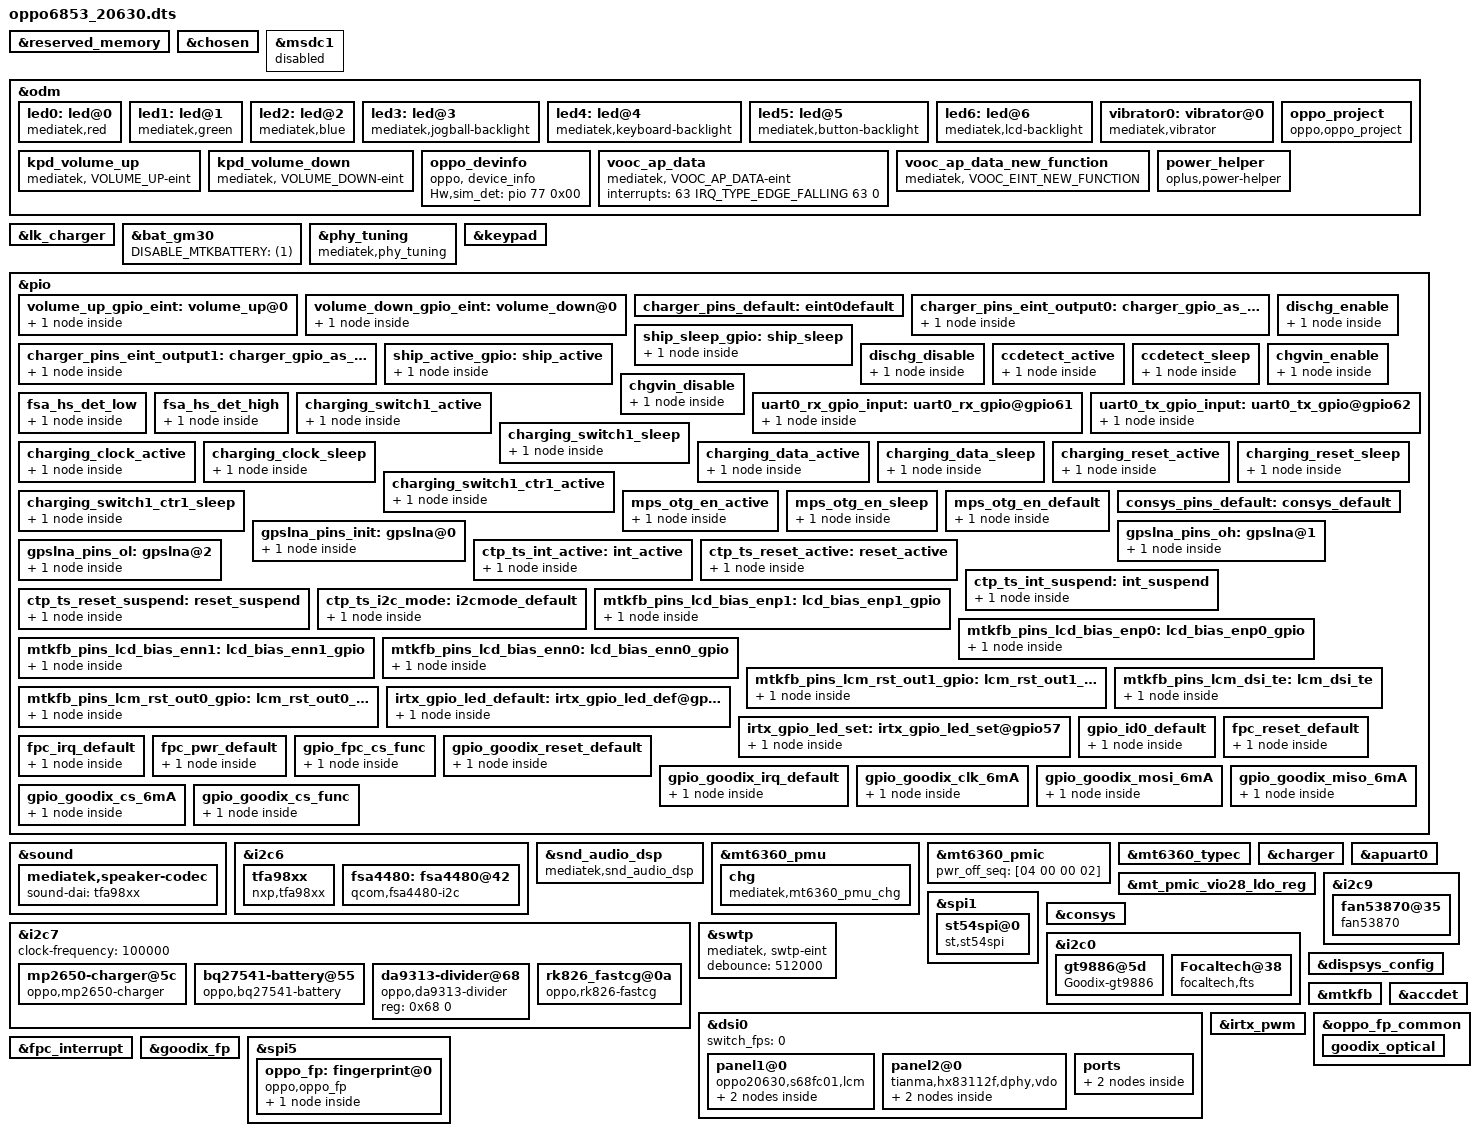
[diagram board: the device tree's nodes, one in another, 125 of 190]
/*
 * Mediatek's mt6853 SoC device tree source
 *
 * Copyright (C) 2016 MediaTek Inc.
 *
 * This program is free software; you can redistribute it and/or modify
 * it under the terms of the GNU General Public License version 2 as
 * published by the Free Software Foundation.
 *
 * This program is distributed in the hope that it will be useful,
 * but WITHOUT ANY WARRANTY; without even the implied warranty of
 * MERCHANTABILITY or FITNESS FOR A PARTICULAR PURPOSE.
 * See http://www.gnu.org/licenses/gpl-2.0.html for more details.
 */
/dts-v1/;
/plugin/;
#include <dt-bindings/interrupt-controller/irq.h>
#include <dt-bindings/interrupt-controller/arm-gic.h>
#include <dt-bindings/pinctrl/mt6853-pinfunc.h>

&reserved_memory {
};

/* chosen */
&chosen {

	atag,videolfb-fb_base_l = <0x7e605000>;
	atag,videolfb-fb_base_h = <0x0>;
	atag,videolfb-islcmfound = <1>;
	atag,videolfb-islcm_inited = <0>;
	atag,videolfb-fps= <6000>;
	atag,videolfb-vramSize= <0x1be0000>;
	atag,videolfb-lcmname=
		"nt35595_fhd_dsi_cmd_truly_nt50358_drv";
};

//ifdef VENDOR_EDIT
/*WeiZhenXi@RM.BSP.Storage.sdcard disable msdc1 for screen*/
&msdc1 {
	status = "disable";
};
//endif VENDOR_EDIT
&odm {
	led0:led@0 {
		compatible = "mediatek,red";
		led_mode = <0>;
		data = <1>;
		pwm_config = <0 0 0 0 0>;
	};
	led1:led@1 {
		compatible = "mediatek,green";
		led_mode = <0>;
		data = <1>;
		pwm_config = <0 0 0 0 0>;
	};
	led2:led@2 {
		compatible = "mediatek,blue";
		led_mode = <0>;
		data = <1>;
		pwm_config = <0 0 0 0 0>;
	};
	led3:led@3 {
		compatible = "mediatek,jogball-backlight";
		led_mode = <0>;
		data = <1>;
		pwm_config = <0 0 0 0 0>;
	};
	led4:led@4 {
		compatible = "mediatek,keyboard-backlight";
		led_mode = <0>;
		data = <1>;
		pwm_config = <0 0 0 0 0>;
	};
	led5:led@5 {
		compatible = "mediatek,button-backlight";
		led_mode = <0>;
		data = <1>;
		pwm_config = <0 0 0 0 0>;
	};
	led6:led@6 {
		compatible = "mediatek,lcd-backlight";
		led_mode = <4>;
		data = <1>;
		pwm_config = <0 1 0 0 0>;
	};
	vibrator0:vibrator@0 {
		compatible = "mediatek,vibrator";
		//#ifdef VENDOR_EDIT
		/* Xing.Xiong@EXP.BSP.Kernel.Driver.998782, 2017/05/16, Modify for vibrator time less than 9ms */
		vib_timer = <30>;
		vib_limit = <0>;
		//#else
		//vib_timer = <25>;
		//vib_limit = <9>;
		//#endif /* VENDOR_EDIT */
		vib_vol= <11>;
	};
//	usb_c_pinctrl:usb_c_pinctrl {
//		compatible = "mediatek,usb_c_pinctrl";
//	};

/*VENDOR_EDIT keypad start*/
/*Bin.Li@EXP.BSP.bootloader.bootflow, 2017/05/16, Add volume up and down */
	kpd_volume_up:kpd_volume_up {
		compatible = "mediatek, VOLUME_UP-eint";
		interrupt-parent = <&pio>;
		interrupts = <1 IRQ_TYPE_EDGE_FALLING 1 0>;
		debounce = <32000>;
		status = "okay";
	};

	kpd_volume_down:kpd_volume_down {
		compatible = "mediatek, VOLUME_DOWN-eint";
		interrupt-parent = <&pio>;
		interrupts = <80 IRQ_TYPE_EDGE_FALLING 80 0>;
		debounce = <32000>;
		status = "okay";
	};
/*VENDOR_EDIT keypad end*/

//#ifdef VENDOR_EDIT
/*Bin.Li@EXP.BSP.bootloader.bootflow, 2017/05/15, Add for oppo project */
	oppo_project:oppo_project {
		compatible = "oppo,oppo_project";
	};
	oppo_devinfo:oppo_devinfo {
		compatible = "oppo, device_info";
	};
//#endif /*VENDOR_EDIT*/
	vooc_ap_data:vooc_ap_data {
		compatible = "mediatek, VOOC_AP_DATA-eint";
		interrupts = <63 IRQ_TYPE_EDGE_FALLING 63 0>;
	};
	vooc_ap_data_new_function:vooc_ap_data_new_function {
		compatible = "mediatek, VOOC_EINT_NEW_FUNCTION";
	};

};

&lk_charger{
	charger_by_buckboost;
	chgic_id = <0>;
};
&bat_gm30 {
	DISABLE_MTKBATTERY = <(1)>;
};
&phy_tuning {
	compatible = "mediatek,phy_tuning";
	u2_vrt_ref = <7>;
	u2_term_ref = <7>;
	u2_enhance = <3>;

	host_u2_vrt_ref = <6>;
	host_u2_term_ref = <6>;
	host_u2_enhance = <2>;
};
/*VENDOR_EDIT*/
/*Bin.Li@EXP.BSP.bootloader.bootflow, 2017/05/16, Add volume up and down*/
&keypad {
	keypad,volume-up	= <&pio 1 0x00>;
	keypad,volume-down	= <&pio 80 0x00>;
	pinctrl-names = "volume_up_as_int", "volume_down_as_int";
	pinctrl-0 = <&volume_up_gpio_eint>;
	pinctrl-1 = <&volume_down_gpio_eint>;
	status = "okay";
};
&pio {
	volume_up_gpio_eint:volume_up@0{
		pins_cmd_dat {
			pinmux = <PINMUX_GPIO1__FUNC_GPIO1>;
			slew-rate = <0>;  /*direction 0:in, 1:out*/
			input-enable;
		};
	};

	volume_down_gpio_eint:volume_down@0{
		pins_cmd_dat {
			pinmux = <PINMUX_GPIO80__FUNC_GPIO80>;
			slew-rate = <0>;  /*direction 0:in, 1:out*/
			input-enable;
		};
	};
};
/*VENDOR_EDIT*/

&oppo_devinfo {
	Hw,sim_det = <&pio 77 0x00>;
};

/*VENDOR_EDIT*/
/* Hefeng.Wu@RM.MM.AudioDriver.Platform, 2020/06/05, add for project compatible */
&sound {
	mediatek,speaker-codec {
		sound-dai = <&tfa98xx>;
	};
};

&i2c6 {
    #address-cells = <1>;
    #size-cells = <0>;

    tfa98xx: tfa98xx {
        compatible = "nxp,tfa98xx";
        reg = <0x34>;
        #sound-dai-cells = <0>;
        reset-gpio = <&pio 139 0>;
        tfa_min_range = <5000>;
        tfa_max_range = <8000>;
        status = "okay";
    };

    fsa4480: fsa4480@42 {
        compatible = "qcom,fsa4480-i2c";
        reg = <0x42>;
        pinctrl-names = "hs_det_gpio_low","hs_det_gpio_high";
        pinctrl-0 = <&fsa_hs_det_low>;
        pinctrl-1 = <&fsa_hs_det_high>;
        fsa4480,hs-det-gpio = <&pio 128 0>;
    };
};
/*VENDOR_EDIT*/

&snd_audio_dsp {
	compatible = "mediatek,snd_audio_dsp";
	mtk_dsp_voip = <0x1f 0x1 0xffffffff 0xffffffff 0x30000>;
	mtk_dsp_primary = <0x1f 0x0 0xffffffff 0xffffffff 0x30000>;
	mtk_dsp_offload = <0x0 0x6 0xffffffff 0xffffffff 0x400000>;
	mtk_dsp_deep = <0x5 0x3 0xffffffff 0xffffffff 0x30000>;
	mtk_dsp_playback = <0x1 0x4 0x10 0x14 0x30000>;
	mtk_dsp_music = <0x1 0xffffffff 0xffffffff 0xffffffff 0x0>;
	mtk_dsp_capture1 = <0x1 0xffffffff 0xd 0x13 0x20000>;
	mtk_dsp_a2dp = <0x0 0xffffffff 0xffffffff 0xffffffff 0x40000>;
	mtk_dsp_dataprovider = <0x0 0xffffffff 0xf 0xffffffff 0x30000>;
	mtk_dsp_call_final = <0x1 0x4 0x10 0x14 0x18000>;
	mtk_dsp_fast = <0x5 0x2 0xffffffff 0xffffffff 0x5000>;
	mtk_dsp_ktv = <0x1 0x8 0x12 0xffffffff 0x10000>;
	mtk_dsp_ver = <0x1>;
	swdsp_smartpa_process_enable = <0x1 0x40000>;
};


/* Charging Start */

&mt6360_pmu {
	mt6360,intr_gpio_num = <10>; /* direct defined GPIO num */
	mt6360,intr_gpio = <&pio 10 0x0>;
};

&mt6360_pmic {
	pwr_off_seq = [04 00 00 02];
};

&mt6360_typec {
	mt6360pd,intr_gpio_num = <9>; /* direct defined GPIO num */
	mt6360pd,intr_gpio = <&pio 9 0x0>;
	//mt6360pd,pcb_gpio = <&pio 57 0x0>;
	//mt6360pd,pcb_gpio_num = <57>;
	mt-tcpc,role_def = <4>;
};

&mt6360_pmu {
	chg {
		compatible = "mediatek,mt6360_pmu_chg";
		interrupt-parent = <&mt6360_pmu>;
		interrupts = <4 0>, <6 0>, <7 0>, <9 0>,
				<12 0>, <13 0>, <14 0>, <15 0>,
				<27 0>, <29 0>, <30 0>, <32 0>,
				<35 0>, <40 0>, <48 0>, <60 0>,
				<53 0>;
		interrupt-names = "chg_treg_evt", "chg_mivr_evt",
				"pwr_rdy_evt", "chg_batsysuv_evt",
				"chg_vsysuv_evt", "chg_vsysov_evt",
				"chg_vbatov_evt", "chg_vbusov_evt",
				"chg_tmri", "chg_adpbadi",
				"chg_rvpi",  "chg_aiccmeasl",
				"wdtmri", "pumpx_donei",
				"attachi", "chrdet_ext_evt",
				"hvdcp_det";
		io-channels = <&adc 0>, <&adc 1>, <&adc 3>, <&adc 4>,
				<&adc 5>, <&adc 6>, <&adc 8>, <&adc 10>;
		io-channel-names = "USBID", "VBUSDIV5", "VSYS", "VBAT",
				"IBUS", "IBAT", "TEMP_JC", "TS";
		chg_name = "primary_chg";
		ichg = <2000000>;               /* uA */
		aicr = <500000>;                /* uA */
		mivr = <4400000>;               /* uV */
		cv = <4350000>;                 /* uA */
		ieoc = <150000>;                /* uA */
		safety_timer = <12>;            /* hour */
		ircmp_resistor = <25000>;       /* uohm */
		ircmp_vclamp = <32000>;         /* uV */
		en_te = <1>;
		en_wdt = <1>;
		aicc_once = <1>;
		post_aicc = <1>;
		batoc_notify = <0>;
	};
};



&charger {
	io-channels = <&auxadc 3>,
		<&auxadc 4>,
		<&auxadc 5>;
	io-channel-names = "auxadc3-charger_id",
		"auxadc4-usb_temp_v_l",
		"auxadc5-usb_temp_v_r";

	pinctrl-names = "default", "charger_gpio_as_output_low", "charger_gpio_as_output_high", "ship_sleep", "ship_active", 
		"dischg_enable", "dischg_disable",
		"chgvin_enable", "chgvin_disable",
		"ccdetect_active","ccdetect_sleep";
	pinctrl-0 = <&charger_pins_default>;
	pinctrl-1 = <&charger_pins_eint_output0>;//USB_ON
	pinctrl-2 = <&charger_pins_eint_output1>;//USB_ON
	pinctrl-3 = <&ship_sleep_gpio>;
	pinctrl-4 = <&ship_active_gpio>;
	pinctrl-5 = <&dischg_enable>;
	pinctrl-6 = <&dischg_disable>;
	pinctrl-7 = <&chgvin_enable>;
	pinctrl-8 = <&chgvin_disable>;
	//pinctrl-5 = <&shortc_active_gpio>;
	pinctrl-9 = <&ccdetect_active>;
	pinctrl-10 = <&ccdetect_sleep>;

	qcom,input_current_charger_ma = <2000>;
	qcom,pd_input_current_charger_ma = <2000>;
	qcom,qc_input_current_charger_ma = <2000>;
	qcom,input_current_usb_ma = <500>;

	qcom,input_current_cdp_ma = <1500>;
	qcom,input_current_led_ma = <1200>;
	qcom,input_current_led_ma_high = <1200>;
	qcom,input_current_led_ma_warm = <1500>;
	qcom,input_current_led_ma_normal = <2000>;
	qcom,led_warm_bat_decidegc = <350>;
	qcom,led_high_bat_decidegc = <370>;

	qcom,input_current_camera_ma = <1200>;
			
	qcom,input_current_vooc_led_ma_high = <1200>;
	qcom,input_current_vooc_led_ma_warm = <1800>;
	qcom,input_current_vooc_led_ma_normal = <3600>;
	qcom,input_current_vooc_ma_normal = <3600>;
	qcom,vooc_temp_bat_normal_decidegc = <350>;
	qcom,input_current_vooc_ma_warm = <3200>;
	qcom,vooc_temp_bat_warm_decidegc = <370>;
	qcom,input_current_vooc_ma_high = <2200>;
	qcom,vooc_temp_bat_hot_decidegc = <440>;

	qcom,charger_current_vooc_ma_normal = <1800>;

	qcom,chg_ctrl_by_calling;
	qcom,input_current_calling_ma = <1500>;

	qcom,overtemp_bat_decidegc = <350>;
	qcom,iterm_disabled = <0>;
	qcom,iterm_ma = <115>;
	qcom,recharge-mv = <100>;
	qcom,batt_capacity_mah = <4300>;/*typical capacity*/

	qcom,removed_bat_decidegc = <190>;  /*<-19C*/

	qcom,cold_bat_decidegc = <20>;  /*-2C~0C*/
	qcom,temp_cold_vfloat_mv = <3980>;
	qcom,temp_cold_fastchg_current_ma = <300>;

	qcom,little_cold_bat_decidegc = <0>;    /*0C~5C*/
	qcom,temp_little_cold_vfloat_mv = <4435>;
	qcom,temp_little_cold_fastchg_current_ma_high = <950>;
	qcom,temp_little_cold_fastchg_current_ma_low = <950>;
	qcom,temp_little_cold_fastchg_current_ma = <950>;
	qcom,pd_temp_little_cold_fastchg_current_ma_high = <1800>;
	qcom,pd_temp_little_cold_fastchg_current_ma_low = <1500>;
	qcom,qc_temp_little_cold_fastchg_current_ma_high = <1800>;
	qcom,qc_temp_little_cold_fastchg_current_ma_low = <1500>;

	qcom,cool_bat_decidegc = <50>;  /*5C~12C*/
	qcom,temp_cool_vfloat_mv = <4435>;
	qcom,temp_cool_fastchg_current_ma_high = <1100>;
	qcom,temp_cool_fastchg_current_ma_low = <1100>;
	qcom,pd_temp_cool_fastchg_current_ma_high = <2000>;
	qcom,pd_temp_cool_fastchg_current_ma_low = <1500>;
	qcom,qc_temp_cool_fastchg_current_ma_high = <2000>;
	qcom,qc_temp_cool_fastchg_current_ma_low = <1500>;

	qcom,little_cool_bat_decidegc = <120>;  /*12C~16C*/
	qcom,temp_little_cool_vfloat_mv = <4435>;
	qcom,temp_little_cool_fastchg_current_ma = <1100>;
	qcom,pd_temp_little_cool_fastchg_current_ma = <2000>;
	qcom,qc_temp_little_cool_fastchg_current_ma = <2000>;

	qcom,normal_bat_decidegc = <160>;       /*16C~44C*/
	qcom,temp_normal_fastchg_current_ma = <1100>;
	qcom,temp_normal_vfloat_mv = <4435>;
	qcom,pd_temp_normal_fastchg_current_ma = <2000>;
	qcom,qc_temp_normal_fastchg_current_ma = <2000>;

	qcom,warm_bat_decidegc = <450>;         /*45C~53C*/ /*8pin Bat Vooc project need add 3 degree C*/
	qcom,temp_warm_vfloat_mv = <4130>;
	qcom,temp_warm_fastchg_current_ma = <550>;
	qcom,pd_temp_warm_fastchg_current_ma = <600>;
	qcom,qc_temp_warm_fastchg_current_ma = <600>;
	qcom,temp_warm_fastchg_current_ma_led_on = <250>;

	qcom,hot_bat_decidegc = <530>;

	qcom,non_standard_vfloat_mv = <3980>;
	qcom,non_standard_fastchg_current_ma = <512>;

	qcom,short_c_bat_cv_mv = <4330>;
	qcom,short_c_bat_vfloat_mv = <3800>;
	qcom,short_c_bat_fastchg_current_ma = <512>;

	qcom,cold_vfloat_sw_limit = <3930>;
	qcom,little_cold_vfloat_sw_limit = <4385>;
	qcom,cool_vfloat_sw_limit = <4385>;
	qcom,little_cool_vfloat_sw_limit = <4385>;
	qcom,normal_vfloat_sw_limit = <4385>;
	qcom,warm_vfloat_sw_limit = <4080>;
	qcom,non_standard_vfloat_sw_limit = <3930>;
	qcom,short_c_bat_vfloat_sw_limit = <3750>;

	qcom,max_chg_time_sec = <61920>;
	qcom,charger_hv_thr = <9900>;
	qcom,charger_recv_thr = <9500>;
	qcom,charger_lv_thr = <3400>;
	qcom,vbatt_full_thr = <4435>;
	qcom,vbatt_hv_thr = <4600>;
	qcom,vfloat_step_mv = <8>;
	qcom,non_standard_vfloat_over_sw_limit = <3990>;
	qcom,cold_vfloat_over_sw_limit = <3990>;
	qcom,little_cold_vfloat_over_sw_limit = <4445>;
	qcom,cool_vfloat_over_sw_limit = <4445>;
	qcom,little_cool_vfloat_over_sw_limit = <4445>;
	qcom,normal_vfloat_over_sw_limit = <4445>;
	qcom,warm_vfloat_over_sw_limit = <4140>;

	qcom,vbatt_power_off = <3300>;
	qcom,vbatt_soc_1 = <3310>;
	qcom,vooc_project = <3>;
	qcom,vbatt_num = <2>;
	qcom,new_ui_warning_support;
	qcom,ffc_support;
	qcom,dual_ffc;
	recharge_after_full;

	qcom,normal_vterm_hw_inc = <18>;
	qcom,non_normal_vterm_hw_inc = <18>;

	qcom,ff1_normal_fastchg_ma = <550>;
	qcom,ff1_warm_fastchg_ma = <550>;

	qcom,ffc2_normal_fastchg_ma = <350>;/*12C~35c*/
	qcom,ffc2_temp_warm_decidegc = <350>;
	qcom,ffc2_warm_fastchg_ma = <350>;/*35C~40c*/
	qcom,ffc2_temp_high_decidegc = <400>;
	qcom,ffc2_temp_low_decidegc = <120>;
	qcom,ffc2_exit_step_ma = <150>;
	qcom,ff1_exit_step_ma = <150>;
	qcom,ff1_warm_exit_step_ma = <150>;

	qcom,ffc_normal_vfloat_sw_limit = <4455>;
	qcom,ffc_warm_vfloat_sw_limit = <4450>;
	qcom,ffc2_normal_vfloat_sw_limit = <4445>;
	qcom,ffc2_warm_vfloat_sw_limit = <4440>;
	qcom,ffc_temp_normal_vfloat_mv = <4500>;
	qcom,ffc1_temp_normal_vfloat_mv = <4500>;
	qcom,ffc2_temp_normal_vfloat_mv = <4500>;
	qcom,ffc_normal_vfloat_over_sw_limit = <4500>;
	qcom,ffc1_normal_vfloat_over_sw_limit = <4500>;
	qcom,ffc2_normal_vfloat_over_sw_limit = <4500>;

	qcom,default_iterm_ma = <115>;
	qcom,default_temp_normal_fastchg_current_ma = <1100>;
	qcom,default_normal_vfloat_sw_limit = <4385>;
	qcom,default_temp_normal_vfloat_mv = <4435>;
	qcom,default_normal_vfloat_over_sw_limit = <4445>;

	qcom,default_temp_little_cool_fastchg_current_ma = <1100>;
	qcom,default_little_cool_vfloat_sw_limit = <4385>;
	qcom,default_temp_little_cool_vfloat_mv = <4435>;
	qcom,default_little_cool_vfloat_over_sw_limit = <4445>;

	qcom,check_batt_full_by_sw;
	qcom,external_gauge;
	qcom,chg_ctrl_by_lcd;
	qcom,chg_ctrl_by_vooc;
	qcom,chg_ctrl_by_camera;
	qcom,sw_vfloat_over_protect_enable;
	qcom,lpd-disable;
	qcom,hv_flashled_support;
	//for PD9V or QC9V
	qcom,vbatt_pdqc_to_5v_thr = <4100>;

	//GPIO config:
	qcom,chargerid_switch-gpio = <&pio 40 0x00>;//USB_ON
	qcom,ship-gpio = <&pio 16 0x00>;
	qcom,dischg-gpio = <&pio 39 0x00>;//VBUS_SHORT
	//qcom,shortc-gpio = <&pio 121 0x00>;
	qcom,chgvin = <&pio 131 0x00>;
	qcom,ccdetect-gpio = <&pio 92 0x00>;//USB_ACC_INT
};
//#ifdef VENDOR_EDIT
//laq@PSW.BSP.sensor, 2020/04/26, Add for 20001 als&ps
&mt_pmic_vio28_ldo_reg {
	regulator-name = "vio28";
	regulator-min-microvolt = <3000000>;
	regulator-max-microvolt = <3000000>;
	regulator-enable-ramp-delay = <240>;
};
//#endif /* VENDOR_EDIT */

&pio {
	charger_pins_default: eint0default {
	};

	charger_pins_eint_output0: charger_gpio_as_output_low {
		pins_cmd_dat {
			pinmux = <PINMUX_GPIO40__FUNC_GPIO40>;
			slew-rate = <1>;
			output-low;
		};
	};

	charger_pins_eint_output1: charger_gpio_as_output_high {
		pins_cmd_dat {
			pinmux = <PINMUX_GPIO40__FUNC_GPIO40>;
			slew-rate = <1>;
			output-high;
		};
	};

	ship_sleep_gpio: ship_sleep {
		pins_cmd_dat {
			pinmux = <PINMUX_GPIO16__FUNC_GPIO16>;
			slew-rate = <1>;
			output-low;
		};
	};

	ship_active_gpio: ship_active {
		pins_cmd_dat {
			pinmux = <PINMUX_GPIO16__FUNC_GPIO16>;
			slew-rate = <1>;
			output-high;
		};
	};
	dischg_enable: dischg_enable {
		pins_cmd_dat {
			pinmux = <PINMUX_GPIO39__FUNC_GPIO39>;
			slew-rate = <1>;//0:input direction 1:output direction
			bias-pull-up = <00>;
			output-high;
		};
	};

	dischg_disable: dischg_disable {
		pins_cmd_dat {
			pinmux = <PINMUX_GPIO39__FUNC_GPIO39>;
			slew-rate = <1>;
			bias-pull-down = <00>;
			output-low;
		};
	};

	
	ccdetect_active: ccdetect_active {
		pins_cmd_dat {
			pinmux = <PINMUX_GPIO92__FUNC_GPIO92>;
			input-enable;
			slew-rate = <0>;
			bias-disable;
		};
	};

	ccdetect_sleep: ccdetect_sleep {
		pins_cmd_dat {
			pinmux = <PINMUX_GPIO92__FUNC_GPIO92>;
			input-enable;
			slew-rate = <0>;
			bias-disable;
		};
	};
	chgvin_enable: chgvin_enable {
		pins_cmd_dat {
			pinmux = <PINMUX_GPIO131__FUNC_GPIO131>;
			slew-rate = <1>;//0:input direction 1:output direction
			bias-pull-up = <00>;
			output-low;
		};
	};
	chgvin_disable: chgvin_disable {
		pins_cmd_dat {
			pinmux = <PINMUX_GPIO131__FUNC_GPIO131>;
			slew-rate = <1>;
			bias-pull-down = <00>;
			output-high;
		};
	};
    fsa_hs_det_low: fsa_hs_det_low {
        pins_cmd_dat {
            pinmux = <PINMUX_GPIO128__FUNC_GPIO128>;
            slew-rate = <1>;  /*direction 0:in, 1:out*/
            output-low;
        };
    };

    fsa_hs_det_high: fsa_hs_det_high {
        pins_cmd_dat {
            pinmux = <PINMUX_GPIO128__FUNC_GPIO128>;
            slew-rate = <1>;  /*direction 0:in, 1:out*/
            output-high;
        };
    };
};

//#ifdef VENDOR_EDIT
//LiYue@BSP.CHG.Basic, 2019/10/02, Add for chargerid
&apuart0 {
	pinctrl-names = "uart0_rx_gpio",
			"uart0_tx_gpio";
	pinctrl-0 = <&uart0_rx_gpio_input>;
	pinctrl-1 = <&uart0_tx_gpio_input>;
	status = "okay";
};

&pio {
	uart0_rx_gpio_input:uart0_rx_gpio@gpio61 {
		pins_cmd_dat {
			pinmux = <PINMUX_GPIO61__FUNC_GPIO61>;
			input-enable;
			slew-rate = <0>;
			bias-disable;
		};
	};
	uart0_tx_gpio_input:uart0_tx_gpio@gpio62 {
		pins_cmd_dat {
			pinmux = <PINMUX_GPIO62__FUNC_GPIO62>;
			input-enable;
			slew-rate = <0>;
			bias-disable;
		};
	};
};

//#endif /* VENDOR_EDIT */





&i2c7 {
	status = "okay";
	clock-frequency = <100000>;
	mp2650-charger@5c {
		status = "okay";
		compatible = "oppo,mp2650-charger";
		reg = <0x5c>;
		qcom,mps_otg_en-gpio = <&pio 17 0x00>;
		pinctrl-names = "mps_otg_en_active", "mps_otg_en_sleep", "mps_otg_en_default";
		pinctrl-0 = <&mps_otg_en_active>;
		pinctrl-1 = <&mps_otg_en_sleep>;
		pinctrl-2 = <&mps_otg_en_default>;
	};
	bq27541-battery@55 {
		status = "okay";
		compatible = "oppo,bq27541-battery";
		reg = <0x55 0>;
		qcom,modify-soc-smooth;
		qcom,batt_bq28z610;
		//qcom,bq28z610_need_balancing;
	};

	da9313-divider@68 {
		status = "okay";
		compatible = "oppo,da9313-divider";
		reg = <0x68 0>;
		//qcom,ic_en_mode;
	};

	rk826_fastcg@0a{
		status = "okay";
		compatible = "oppo,rk826-fastcg";
		reg = <0x0a 0>;
		qcom,vooc-low-temp = <50>;
		qcom,oppo_batt_4400mv;
		qcom,support_vooc_by_normal_charger_path;
		qcom,vooc_fw_update_newmethod;
		qcom,vooc-high-temp = <430>;
		qcom,vooc-low-soc = <1>;
		qcom,vooc-high-soc = <90>;
		qcom,vooc-fw-type = <0x20>;

		qcom,vooc_multistep_adjust_current_support;
		qcom,vooc_multistep_initial_batt_temp = <310>;
		qcom,vooc_strategy_normal_current = <0x06>;

		qcom,vooc-normal-to-little-cool-current = <0x05>;
		qcom,vooc_batt_over_high_temp = <440>;
		qcom,vooc_batt_over_low_temp = <45>;
		qcom,vooc_over_high_or_low_current = <0x02>;

		qcom,vooc_strategy1_batt_high_temp0 = <425>;
		qcom,vooc_strategy1_batt_high_temp1 = <430>;
		qcom,vooc_strategy1_batt_high_temp2 = <435>;
		qcom,vooc_strategy1_batt_low_temp2 = <420>;
		qcom,vooc_strategy1_batt_low_temp1 = <415>;
		qcom,vooc_strategy1_batt_low_temp0 = <400>;

		qcom,vooc_strategy1_high_current0 = <0x04>;//4A
		qcom,vooc_strategy1_high_current1 = <0x03>;//3A
		qcom,vooc_strategy1_high_current2 = <0x02>;//2A
		qcom,vooc_strategy1_low_current2 = <0x03>;//3A
		qcom,vooc_strategy1_low_current1 = <0x04>;//4A
		qcom,vooc_strategy1_low_current0 = <0x04>;//4A

		qcom,vooc_strategy2_batt_up_temp1 = <375>;
		qcom,vooc_strategy2_batt_up_down_temp2 = <380>;
		qcom,vooc_strategy2_batt_up_temp3 = <390>;
		qcom,vooc_strategy2_batt_up_down_temp4 = <400>;
		qcom,vooc_strategy2_batt_up_temp5 = <410>;
		qcom,vooc_strategy2_batt_up_temp6 = <415>;
		qcom,vooc_strategy2_high0_current = <0x05>;
		qcom,vooc_strategy2_high1_current = <0x04>;
		qcom,vooc_strategy2_high2_current = <0x03>;
		qcom,vooc_strategy2_high3_current = <0x02>;
		pinctrl-names = "switch1_act_switch2_act", "switch1_sleep_switch2_sleep",
						"switch1_act_switch3_act", "switch1_sleep_switch3_sleep",
						"switch1_act_switch2_sleep", "switch1_sleep_switch2_act",
						"clock_active","clock_sleep",
						"data_active","data_sleep",
						"reset_active","reset_sleep",
						"charging_switch1_ctr1_active","charging_switch1_ctr1_sleep";
		pinctrl-0 = <&charging_switch1_active>;//USB_SW_CTRL1
		pinctrl-1 = <&charging_switch1_sleep>;//USB_SW_CTRL1
		pinctrl-2 = <&charging_switch1_active>;//USB_SW_CTRL1
		pinctrl-3 = <&charging_switch1_sleep>;//USB_SW_CTRL1
		pinctrl-4 = <&charging_switch1_active>;//USB_SW_CTRL1
		pinctrl-5 = <&charging_switch1_sleep>;//USB_SW_CTRL1
		pinctrl-6 = <&charging_clock_active>;//AP_CLK
		pinctrl-7 = <&charging_clock_sleep>;//AP_CLK
		pinctrl-8 = <&charging_data_active>;//AP_DATA
		pinctrl-9 = <&charging_data_sleep>;//AP_DATA
		pinctrl-10 = <&charging_reset_active>;//MCU_EN
		pinctrl-11 = <&charging_reset_sleep>;//MCU_EN
		pinctrl-12 = <&charging_switch1_ctr1_active>;//USB_SW_CTRL2
		pinctrl-13 = <&charging_switch1_ctr1_sleep>;//USB_SW_CTRL2

		qcom,charging_switch1-gpio 		= <&pio 137 0x00>;//USB_SW_CTRL1
		qcom,charging_switch1_ctr1-gpio 	= <&pio 136 0x00>;//USB_SW_CTRL2//must set a gpio


		qcom,charging_reset-gpio 			= <&pio 132 0x00>;//MCU_EN
		qcom,charging_clock-gpio 			= <&pio 64 0x00>;//AP_CLK
		qcom,charging_data-gpio 			= <&pio 63 0x00>;//AP_DATA
	};
};

&pio {
	charging_switch1_active: charging_switch1_active {
		pins_cmd_dat {
			pinmux = <PINMUX_GPIO137__FUNC_GPIO137>;
			slew-rate = <1>;
			output-high;
		};
	};

	charging_switch1_sleep: charging_switch1_sleep {
		pins_cmd_dat {
			pinmux = <PINMUX_GPIO137__FUNC_GPIO137>;
			slew-rate = <1>;
			output-low;
		};
	};

	charging_clock_active: charging_clock_active {
		pins_cmd_dat {
			pinmux = <PINMUX_GPIO64__FUNC_GPIO64>;
			slew-rate = <0>;
			bias-pull-up = <00>;
		};
	};

	charging_clock_sleep: charging_clock_sleep {
		pins_cmd_dat {
			pinmux = <PINMUX_GPIO64__FUNC_GPIO64>;
			slew-rate = <0>;
			bias-pull-down = <00>;
		};
	};

	charging_data_active: charging_data_active {
		pins_cmd_dat {
			pinmux = <PINMUX_GPIO63__FUNC_GPIO63>;
			slew-rate = <0>;
			bias-pull-down = <00>;
		};
	};

	charging_data_sleep: charging_data_sleep {
		pins_cmd_dat {
			pinmux = <PINMUX_GPIO63__FUNC_GPIO63>;
			slew-rate = <0>;
			bias-pull-down = <00>;
		};
	};

	charging_reset_active: charging_reset_active {
		pins_cmd_dat {
			pinmux = <PINMUX_GPIO132__FUNC_GPIO132>;
			slew-rate = <1>;
			output-high;
		};
	};

	charging_reset_sleep: charging_reset_sleep {
		pins_cmd_dat {
			pinmux = <PINMUX_GPIO132__FUNC_GPIO132>;
			slew-rate = <1>;
			output-low;
		};
	};

	charging_switch1_ctr1_active: charging_switch1_ctr1_active {
		pins_cmd_dat {
			pinmux = <PINMUX_GPIO136__FUNC_GPIO136>;
			slew-rate = <1>;
			output-high;
		};
	};
	charging_switch1_ctr1_sleep: charging_switch1_ctr1_sleep {
		pins_cmd_dat {
			pinmux = <PINMUX_GPIO136__FUNC_GPIO136>;
			slew-rate = <1>;
			output-low;
		};
	};

	mps_otg_en_active: mps_otg_en_active {
		pins_cmd_dat {
			pinmux = <PINMUX_GPIO17__FUNC_GPIO17>;
			slew-rate = <1>;
			output-high;
		};
	};

	mps_otg_en_sleep: mps_otg_en_sleep {
		pins_cmd_dat {
			pinmux = <PINMUX_GPIO17__FUNC_GPIO17>;
			slew-rate = <1>;
			output-low;
		};
	};

	mps_otg_en_default: mps_otg_en_default {
		pins_cmd_dat {
			pinmux = <PINMUX_GPIO17__FUNC_GPIO17>;
			slew-rate = <1>;
			output-low;
		};
	};

};

/*#ifdef VENDOE_EDIT*/
/* Shengguang.Zhu@Cam.Drv, 20200518,  sensor porting!*/
&i2c9 {
       status = "okay";
	   fan53870@35 {
               compatible = "fan53870";
               reg = <0x35>;
               ldo1_min_vol = <800000>;  /*uV*/
               ldo1_max_vol = <1504000>;
               ldo1_step_vol = <8000>;
       };
};
/*#endif*/


//#ifdef VENDOR_EDIT
//Zhou.Zheng@CN.NFC.Basic.Hardware,2714107,2020/04/13,Add for:5G-B device
//NFC GPIO start
&spi1 {
	st54spi@0 {
		compatible = "st,st54spi";
		reg = <0>;
		spi-max-frequency = <1000000> ;
		gpio-power = <8>;
		gpio-power-std = <&pio 8 0x0>;
		status = "okay";
	};
};
//NFC GPIO end
//#endif /* VENDOR_EDIT */

/* CONSYS GPIO standardization */
&pio {
	consys_pins_default: consys_default {
	};
	gpslna_pins_init: gpslna@0 {
		pins_cmd_dat {
			pinmux = <PINMUX_GPIO87__FUNC_GPIO87>;
			output-low;
		};
	};
	gpslna_pins_oh: gpslna@1 {
		pins_cmd_dat {
			pinmux = <PINMUX_GPIO87__FUNC_GPS_L1_ELNA_EN>;
		};
	};
	gpslna_pins_ol: gpslna@2 {
		pins_cmd_dat {
			pinmux = <PINMUX_GPIO87__FUNC_GPIO87>;
			output-low;
		};
	};
};

&consys {
	pinctrl-names = "default", "gps_lna_state_init",
		"gps_lna_state_oh", "gps_lna_state_ol";
	pinctrl-0 = <&consys_pins_default>;
	pinctrl-1 = <&gpslna_pins_init>;
	pinctrl-2 = <&gpslna_pins_oh>;
	pinctrl-3 = <&gpslna_pins_ol>;
	status = "okay";
};

&i2c0 {
	status = "okay";
        gt9886@5d{
                compatible = "Goodix-gt9886";
                reg = <0x5d>;
                chip-name = "GT9886";

                interrupt-parent = <&pio>;
                interrupts = <14 IRQ_TYPE_EDGE_FALLING 14 0>;
                irq-gpio = <&pio 14 0x2002>;
                reset-gpio = <&pio 138 0>;
                bisa-gpio = <&pio 140 0>;

                touchpanel,max-num-support = <10>;
                touchpanel,tx-rx-num = <15 34>;
                touchpanel,panel-coords = <1080 2400>;
                touchpanel,display-coords = <1080 2400>;
                touchpanel,touchmajor-limit = <0 54>;
                vdd_2v8-supply  = <&mt_pmic_vtp_ldo_reg>;
                /* SW Support Feature Control */
                project_id = <20630>;
                register-is-16bit;
                black_gesture_support;
                fw_edge_limit_support;
                pressure_report_support;
                charger_pump_support;
                game_switch_support;
                smart_gesture_support;
                fw_update_app_support;
                fingerprint_underscreen_support;
                headset_pump_support;
                esd_handle_support;
                new_set_irq_wake_support;
                irq_need_dev_resume_ok;
                /*
                 *Virtual Key Config:
                 *1:touchpanel,button-type: <virtualkey_type  supportted_button-map>
                 *virtualkey_type:
                 *Type 1: using board_properties
                 *Type 2: using same IC (button zone&& touch zone are seprate)
                 *Type 3: using diffrent IC (button zone&& touch zone are seprate)
                 *Type 4: No need of virtual key process
                 *supportted_button-map:select|menu|home|back
                 *
                 *2:touchpanel,button-map
                 *type (X1,Y1)(X2,Y2)(X3,Y3)(Width_X,Hight_Y)--Only when button-type is 0
                 */
                touchpanel,button-type = <4>;
                touchpanel.button-TRx = <0 0>;
        };
	 Focaltech@38 {
               compatible = "focaltech,fts";
               reg = <0x38>;
               chip-name = "FT3518";

               /* Interrupt && Irq-gpio */
               interrupt-parent = <&pio>;
               interrupts = <14 IRQ_TYPE_EDGE_FALLING 14 0>;
               irq-gpio = <&pio 14 0x2002>;
               reset-gpio = <&pio 138 0>;
               bisa-gpio = <&pio 140 0>;
               pinctrl-names = "default";

               touchpanel,max-num-support = <10>;
               touchpanel,tx-rx-num = <16 34>;
               touchpanel,panel-coords = <1080 2400>;
               touchpanel,display-coords = <1080 2400>;
               touchpanel,touchmajor-limit = <0 54>;
				vdd_2v8-supply  = <&mt_pmic_vtp_ldo_reg>;
               /* SW Support Feature Control */
               project_id = <20630>;
               black_gesture_support;
	       irq_need_dev_resume_ok;
               fw_edge_limit_support;
               pressure_report_support;
               charger_pump_support;
               game_switch_support;
               smart_gesture_support;
               headset_pump_support;
               fw_update_app_support;
               fingerprint_underscreen_support;
               //esd_handle_support;
               touchpanel,button-type = <4>;
               touchpanel.button-TRx = <0 0>;
               };
};

&pio {
	ctp_ts_int_active: int_active {
		pins_cmd_dat {
			pinmux = <PINMUX_GPIO14__FUNC_GPIO14>;
			slew-rate = <0>;
			bias-pull-up = <11>;
		};
	};
	ctp_ts_reset_active: reset_active {
		pins_cmd_dat {
			pinmux = <PINMUX_GPIO138__FUNC_GPIO138>;
			slew-rate = <1>;
			output-high;
		};
	};
	ctp_ts_int_suspend: int_suspend {
		pins_cmd_dat {
			pinmux = <PINMUX_GPIO14__FUNC_GPIO14>;
			slew-rate = <1>;
			output-low;
		};
	};
	ctp_ts_reset_suspend: reset_suspend {
		pins_cmd_dat {
			pinmux = <PINMUX_GPIO138__FUNC_GPIO138>;
			slew-rate = <1>;
			output-low;
		};
	};
	ctp_ts_i2c_mode: i2cmode_default {
		pins_cmd_dat {
			pinmux = <PINMUX_GPIO97__FUNC_SCL0>,
				<PINMUX_GPIO98__FUNC_SDA0>;
		};
	};

};
//#endif Add Oppo Tp DTS
/* TOUCH end */

//#ifdef VENDOR_EDIT
//Anhui.Sun@PSW.NW.RF, 2018/12/19, Add for SWTP - RF cable detection
&swtp {
    compatible = "mediatek, swtp-eint";
    debounce = <512000>;
};
//#endif  /*VENDOR_EDIT*/
#include "cust_mt6853_camera_20630.dtsi"
#include <oppo6853_20630/cust.dtsi>
/* DISPSYS GPIO standardization */

#ifndef CONFIG_FPGA_EARLY_PORTING
&pio {
	mtkfb_pins_lcd_bias_enp1: lcd_bias_enp1_gpio {
		pins_cmd_dat {
			pinmux = <PINMUX_GPIO182__FUNC_GPIO182>;
			slew-rate = <1>;
			output-high;
		};
	};

	mtkfb_pins_lcd_bias_enp0: lcd_bias_enp0_gpio {
		pins_cmd_dat {
			pinmux = <PINMUX_GPIO182__FUNC_GPIO182>;
			slew-rate = <1>;
			output-low;
		};
	};

	mtkfb_pins_lcd_bias_enn1: lcd_bias_enn1_gpio {
		pins_cmd_dat {
			pinmux = <PINMUX_GPIO138__FUNC_GPIO138>;
			slew-rate = <1>;
			output-high;
		};
	};

	mtkfb_pins_lcd_bias_enn0: lcd_bias_enn0_gpio {
		pins_cmd_dat {
			pinmux = <PINMUX_GPIO138__FUNC_GPIO138>;
			slew-rate = <1>;
			output-low;
		};
	};

	mtkfb_pins_lcm_rst_out1_gpio: lcm_rst_out1_gpio {
		pins_cmd_dat {
			pinmux = <PINMUX_GPIO86__FUNC_GPIO86>;
			slew-rate = <1>;
			output-high;
		};
	};

	mtkfb_pins_lcm_rst_out0_gpio: lcm_rst_out0_gpio {
		pins_cmd_dat {
			pinmux = <PINMUX_GPIO86__FUNC_GPIO86>;
			slew-rate = <1>;
			output-low;
		};
	};
	mtkfb_pins_lcm_dsi_te: lcm_dsi_te {
		pins_cmd_dat {
			pinmux = <PINMUX_GPIO84__FUNC_DSI_TE>;
		};
	};
};

&dispsys_config {
	pinctrl-names =
		"lcm_rst_out1_gpio", "lcm_rst_out0_gpio",
		"mode_te_te";
	pinctrl-0 = <&mtkfb_pins_lcm_rst_out1_gpio>;
	pinctrl-1 = <&mtkfb_pins_lcm_rst_out0_gpio>;
	pinctrl-2 = <&mtkfb_pins_lcm_dsi_te>;
	status = "okay";
};

&dsi0 {
	status = "okay";
	#address-cells = <1>;
	#size-cells = <0>;
	switch_fps = <0>;
	panel1@0 {
		compatible = "oppo20630,s68fc01,lcm";
		reg = <0>;
		pm-enable-gpios = <&pio 84 0>;
                reset-gpios = <&pio 86 0>;
                ldo3-supply = <&mt_pmic_vmc_ldo_reg>;
                ldo5-supply = <&mt_pmic_vmch_ldo_reg>;
		pinctrl-names = "default";
		port {
			panel_in1: endpoint {
				remote-endpoint = <&dsi_out>;
		};
			};
	};
	panel2@0 {
                compatible = "tianma,hx83112f,dphy,vdo";
                reg = <1>;
                pm-enable-gpios = <&pio 41 0>;
                reset-gpios = <&pio 86 0>;
                bias-gpios = <&pio 137 0>,
                        <&pio 138 0>;
                pinctrl-names = "default";
                port {
                        panel_in2: endpoint {
                                remote-endpoint = <&dsi_out>;
                };
                        };
        };
	ports {
		port {
			dsi_out: endpoint {
				remote-endpoint = <&panel_in1>;
			};
		};
	};
};

&mtkfb {
	pinctrl-names = "lcd_bias_enp1_gpio", "lcd_bias_enp0_gpio",
		"lcd_bias_enn1_gpio", "lcd_bias_enn0_gpio",
		"lcm_rst_out1_gpio", "lcm_rst_out0_gpio",
		"mode_te_te";
	pinctrl-0 = <&mtkfb_pins_lcd_bias_enp1>;
	pinctrl-1 = <&mtkfb_pins_lcd_bias_enp0>;
	pinctrl-2 = <&mtkfb_pins_lcd_bias_enn1>;
	pinctrl-3 = <&mtkfb_pins_lcd_bias_enn0>;
	pinctrl-4 = <&mtkfb_pins_lcm_rst_out1_gpio>;
	pinctrl-5 = <&mtkfb_pins_lcm_rst_out0_gpio>;
	pinctrl-6 = <&mtkfb_pins_lcm_dsi_te>;
	status = "okay";
};

/* accdet start */
&accdet {
	/* accdet micbias voltage: 0x09:2.85v 0x08:2.8v 0x07,
	 * 2.7v;0x05,2.5v;0x02,1.9v
	 */
	accdet-mic-vol = <8>;
	/* accdet pwm_width, pwm_thresh, fall_delay, rise_delay
	 * debounce0, debounce1, debounce3, debounce4
	 * eint pwm_width, eint pwm_thresh
	 * eint deb(debounce0, debounce1, debounce2, debounce3), inv_debounce
	 */
	headset-mode-setting = <0x500 0x500 1 0x1f0
				0x2000 0x800 0x2000 0x44
				0x0 0x7
				0x5 0x9 0x9 0xd 0xe>;
	accdet-plugout-debounce = <1>;
	/*1:ACC mode, 2:low cost without in bias, 6:low cost with in bias*/
	accdet-mic-mode = <2>;
	/*0--MD_MAX--UP_MAX--DW_MAX*/
	headset-three-key-threshold = <0 82 170 306>;
	headset-three-key-threshold-CDD = <0 121 192 600>;
	/*0--MD_MAX--VOICE_MAX--UP_MAX--DW_MAX*/
	headset-four-key-threshold = <0 58 121 192 400>;


    /* moisture HW mode config start. Enable moisture detection or not
    * default use HW mode for moisture detection
    */
    moisture_detect_enable = <1>;
	/* select VTH to 2v and 500k, use internal resitance */
	eint_use_ext_res = <0>;

    /* enable eint detection mode, if moisture detection enable
     * eint_detect_mode = moisture_detect_mode;otherwise, select
      * eint_detect_mode = 4 as DEFAULT
       */
    eint_detect_mode = <5>;
    /* enable moisture detection mode, if moisture detection enable
     * eint_detect_mode = moisture_detect_mode
     */
    moisture_detect_mode = <5>;
    /* select 0: 2.8V; 1: 2.4V; 2: 2V; 3: VTH=MVTH(VTH2) */
    moisture_comp_vth = <2>;
    /* vref2 voltage for different water impedance */
    moisture_comp_vref2 = <0>;
    /* moisture HW mode config end */

    /* moisture SW mode config start, use external resister or not.
     * DEFAULT NOT NEED
     */
    moisture_use_ext_res = <0>;
    /* moisture external resister ohm, SW mode by auxadc */
    moisture-external-r = <2000000>;
    /* moisture internal resister ohm, SW mode by auxadc */
    moisture-internal-r = <47000>;
    /* moisture of water resister ohm, SW mode by auxadc*/
    moisture-water-r = <10000>;
    /* moisture SW mode config end */
	status = "okay";
};
/* accdet end */

/* IRTX GPIO Start */
&irtx_pwm {
	pinctrl-names = "irtx_gpio_led_default", "irtx_gpio_led_set";
	pinctrl-0 = <&irtx_gpio_led_default>;
	pinctrl-1 = <&irtx_gpio_led_set>;
	status = "okay";
};

&pio {
	/* IRTX GPIO Settings -Start */
	/* default: GPIO0, output, high */
	irtx_gpio_led_default:irtx_gpio_led_def@gpio57 {
		pins_cmd_dat {
			pinmux = <PINMUX_GPIO57__FUNC_GPIO57>;
			slew-rate = <1>;
			bias-disable;
			output-low;
			input-schmitt-enable = <0>;
		};
	};

	irtx_gpio_led_set:irtx_gpio_led_set@gpio57 {
		pins_cmd_dat {
			pinmux = <PINMUX_GPIO57__FUNC_PWM_3>;
			slew-rate = <1>;
			output-high;
		};
	};
}; /* IRTX GPIO Settings -End */

/* FINGERPRINT start */
//ifdef VENDOR_EDIT
//Jiaqi.Wu@BSP.Fingerprint.Basic, 2018/09/10, add for fingerprint
&oppo_fp_common {
    oppo,fp_gpio = <41>;
    oppo,fp_gpio_id = <&pio 41 0x0>;
    pinctrl-names = "default";
    pinctrl-0 = <&gpio_id0_default>;
    goodix_optical {
        oppo,fp-id = <1>; /* fp id mapping table */
        vendor-chip = <11>; /* please refer to the struct fp_vendor_t in oppo_fp_commmon.n */
        eng-menu = "-1,-1"; /* represents SNR, inclination test item in engineer menu, and 0/1 means off/on */
        chip-name = "G_OPTICAL_G3";  /* /proc/fp_id, will be displayed in engineer menu  */
	};
};

&pio{
	gpio_id0_default: gpio_id0_default {
		pins_cmd_dat {
			pinmux = <PINMUX_GPIO41__FUNC_GPIO41>;
			slew-rate = <0>;
			bias-pull-up = <00>;
			input-enable;
		};
	};
};
//ifdef VENDOR_EDIT
/* Jiaqi.Wu@PSW.BSP.Fingerprint.Basic, 2020/02/12, Add for FPC driver baseon trustonic tee */
/* fpc GPIO standardization */

&fpc_interrupt {
	pinctrl-names = "default", "fpc_cs_func";
	fpc,irq-gpio    = <&pio 15 0x00>;
	fpc,reset-gpio  = <&pio 14 0x00>;
	fpc,vdd-en = <&pio 126 0x00>;
	fpc,gpio_cs = <&pio 157 0x00>;
	pinctrl-0 = <&fpc_reset_default>,<&fpc_irq_default>,<&fpc_pwr_default>;
	pinctrl-1 = <&gpio_fpc_cs_func>;
	status = "okay";
};

&pio {
fpc_reset_default: fpc_reset_default {
					   pins_cmd_dat {
						   pinmux = <PINMUX_GPIO6__FUNC_GPIO6>;
						   slew-rate = <1>;
						   output-low;
					   };
				   };
fpc_irq_default: fpc_irq_default {
					 pins_cmd_dat {
						 pinmux = <PINMUX_GPIO7__FUNC_GPIO7>;
						 slew-rate = <0>;
						 bias-pull-up = <00>;
					 };
				 };

fpc_pwr_default: fpc_pwr_default {
					 pins_cmd_dat {
						 pinmux = <PINMUX_GPIO126__FUNC_GPIO126>;
						 slew-rate = <1>;
						 bias-disable;
						 output-low;
					 };
				 };
gpio_fpc_cs_func: gpio_fpc_cs_func {
					  pins_cmd_dat {
						  pinmux = <PINMUX_GPIO29__FUNC_SPI5_CSB>;
						  drive-strength = <3>;
					  };
				  };
};

&goodix_fp {
	goodix,gpio_irq = <&pio 7 0x00>;
	goodix,gpio_reset = <&pio 6 0x00>;
	goodix,gpio_cs = <&pio 29 0x00>;
	pinctrl-names = "default", "gf_spi_drive_6mA", "gf_cs_func";
	pinctrl-0 = <&gpio_goodix_irq_default>, <&gpio_goodix_reset_default>;
	pinctrl-1 = <&gpio_goodix_clk_6mA>, <&gpio_goodix_mosi_6mA>, <&gpio_goodix_miso_6mA>, <&gpio_goodix_cs_6mA>;
	pinctrl-2 = <&gpio_goodix_cs_func>;
	status = "okay";
};

&spi5 {
#address-cells = <1>;
#size-cells = <0>;
status = "okay";
oppo_fp: fingerprint@0 {
		 compatible = "oppo,oppo_fp";
		 reg = <0>;
		 spi-max-frequency = <8000000>;
		 spi-id = <5>;
		 spi-irq = <39>;
		 spi-reg = <11019000>;
		 dvdd-supply = <&mt_pmic_vfp_ldo_reg>;
		 dvdd-config = <1800000 1800000 150000>;
		 power-num = <2>;
		 status = "okay";
		 power_source_1 {
			 power-mode = <1>;
			 power-name = "dvdd";
			 power-config = "dvdd-config";
			 delay-time = <0>;
		 };
	 };
};
/* 1 = ldo power, refer to oppo_fp_common.h*/
&pio{
gpio_goodix_reset_default: gpio_goodix_reset_default {
				   pins_cmd_dat {
					   pinmux = <PINMUX_GPIO6__FUNC_GPIO6>;
					   slew-rate = <1>;
					   output-low;
				   };
			   };
gpio_goodix_irq_default: gpio_goodix_irq_default {
				 pins_cmd_dat {
					 pinmux = <PINMUX_GPIO7__FUNC_GPIO7>;
					 slew-rate = <0>;
					 bias-pull-down;
				 };
			 };
gpio_goodix_clk_6mA: gpio_goodix_clk_6mA {
			     pins_cmd_dat {
				     pinmux = <PINMUX_GPIO28__FUNC_SPI5_CLK>;
				     drive-strength = <2>;
			     };
		     };
gpio_goodix_mosi_6mA: gpio_goodix_mosi_6mA {
			      pins_cmd_dat {
				      pinmux = <PINMUX_GPIO30__FUNC_SPI5_MO>;
				      drive-strength = <2>;
			      };
		      };
gpio_goodix_miso_6mA: gpio_goodix_miso_6mA {
			      pins_cmd_dat {
				      pinmux = <PINMUX_GPIO31__FUNC_SPI5_MI>;
				      drive-strength = <3>;
			      };
		      };
gpio_goodix_cs_6mA: gpio_goodix_cs_6mA {
			    pins_cmd_dat {
				    pinmux = <PINMUX_GPIO29__FUNC_SPI5_CSB>;
				    drive-strength = <2>;
			    };
		    };
gpio_goodix_cs_func: gpio_goodix_cs_func {
			     pins_cmd_dat {
				     pinmux = <PINMUX_GPIO29__FUNC_SPI5_CSB>;
				     drive-strength = <2>;
			     };
		     };
};
//#endif

&odm{
        power_helper {
                compatible = "oplus,power-helper";
        };
};

#endif
/*End of this file, DO NOT ADD ANYTHING HERE*/

